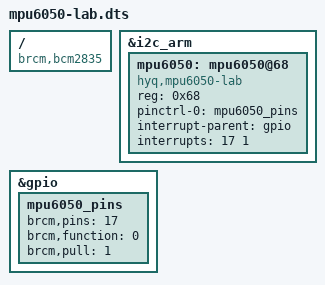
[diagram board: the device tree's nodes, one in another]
// SPDX-License-Identifier: GPL-2.0
/*
 * Raspberry Pi overlay for mpu6050_lab.
 *
 *   MPU-6050 VCC -> 3V3 (pin 1)   GND -> pin 9
 *   SDA -> GPIO2 (pin 3)   SCL -> GPIO3 (pin 5)
 *   INT -> GPIO17 (pin 11)  AD0 -> GND (address 0x68)
 *
 * Build:   dtc -@ -I dts -O dtb -o mpu6050-lab.dtbo mpu6050-lab.dts
 * Enable:  copy to /boot/firmware/overlays/ and add to config.txt
 *            dtparam=i2c_arm=on
 *            dtoverlay=mpu6050-lab            (INT on GPIO17)
 *            dtoverlay=mpu6050-lab,int_pin=27 (INT elsewhere)
 *
 * The overlay only describes the chip.  Leave the "interrupts" property out
 * (or wire nothing to INT) and the driver falls back to its hrtimer mode.
 */
/dts-v1/;
/plugin/;

/ {
	compatible = "brcm,bcm2835", "brcm,bcm2836", "brcm,bcm2837", "brcm,bcm2711";

	fragment@0 {
		target = <&i2c_arm>;
		__overlay__ {
			#address-cells = <1>;
			#size-cells = <0>;
			status = "okay";

			mpu6050: mpu6050@68 {
				compatible = "hyq,mpu6050-lab";
				reg = <0x68>;
				pinctrl-names = "default";
				pinctrl-0 = <&mpu6050_pins>;
				interrupt-parent = <&gpio>;
				interrupts = <17 1>;	/* GPIO17, rising edge */
			};
		};
	};

	fragment@1 {
		target = <&gpio>;
		__overlay__ {
			mpu6050_pins: mpu6050_pins {
				brcm,pins = <17>;
				brcm,function = <0>;	/* input */
				brcm,pull = <1>;	/* pull-down: INT idles low */
			};
		};
	};

	__overrides__ {
		int_pin = <&mpu6050_pins>, "brcm,pins:0",
			  <&mpu6050>, "interrupts:0";
	};
};
